# ATA8510 device description
Architecture: AVR8; Family: megaAVR
Registers are 8-bit, access not given, no defined reset value unless marked. A register's access mark holds for its fields unless they carry their own. Offsets are from the block's base; [hi:lo] are bit positions; {n}, {i} and the like mark numbered series.

## SUP
Instances: SUP 0x00
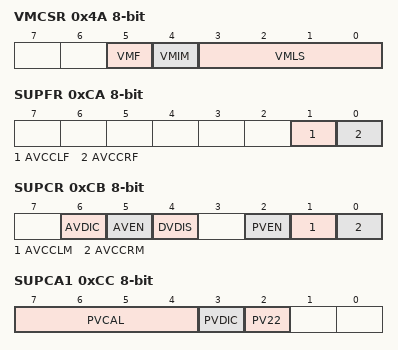
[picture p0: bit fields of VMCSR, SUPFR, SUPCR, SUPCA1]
0x4A VMCSR — Voltage Monitor Control and Status Register
  [5] VMF — Voltage Monitor Flag
  [4] VMIM — Voltage Monitor Interrupt Mask
  [3:0] VMLS — Voltage Monitor Level Select
0xCA SUPFR — Supply Interrupt Flag Register
  [1] AVCCLF — AVCC low interrupt flag
  [0] AVCCRF — AVCC reset interrupt flag
0xCB SUPCR — Supply Control Register
  [6] AVDIC — AVCC Double Internal Current
  [5] AVEN — AVCC Enable
  [4] DVDIS — DVCC Disable
  [2] PVEN — Power amplifier Voltage supply Enable
  [1] AVCCLM — AVCC Low Interrupt Mask Bit
  [0] AVCCRM — AVCC Reset Interrupt Mask Bit
0xCC SUPCA1 — Supply calibration register 1
  [7:4] PVCAL — Power Amplifier Regulator Calibration
  [3] PVDIC — Power Amplifier Regulator Double Internal Current
  [2] PV22 — Power Amplifier Voltage 2.2V
0xCD SUPCA2 — Supply calibration register 2
  [3:0] BGCAL — Band Gap Calibration
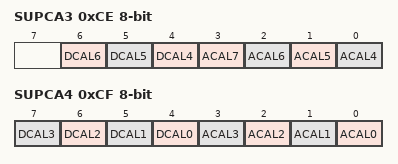
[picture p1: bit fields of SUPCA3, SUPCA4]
0xCE SUPCA3 — Supply calibration register 3
  [6] DCAL6 — DVCC Reset Threshold Calibration bit 6
  [5] DCAL5 — DVCC Reset Threshold Calibration bit 5
  [4] DCAL4 — DVCC Reset Threshold Calibration bit 4
  [n-4] ACAL{n} (n=4..7) — AVCC Reset Threshold Calibration bit {n}
0xCF SUPCA4 — Supply calibration register 4
  [n+4] DCAL{n} (n=0..3) — DVCC Regulator Output Voltage Calibration bit {n}
  [n] ACAL{n} (n=0..3) — AVCC Regulator Output Voltage Calibration bit {n}
0xD0 CALRDY — Calibration ready signature
0xD1 VMCAL — Voltage Monitor Calibration register
  [2:0] VMCAL — Voltage monitor calibration

## SYMCH
Instances: SYMCH 0x00
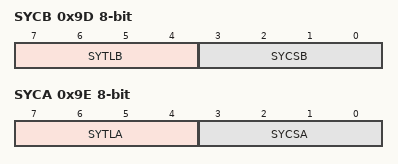
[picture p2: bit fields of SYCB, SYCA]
0x9D SYCB — Symbol check configuration for data path B
  [7:4] SYTLB — Symbol timing limit for path B
  [3:0] SYCSB — Symbol Check check size for data path B
0x9E SYCA — Symbol check configuration for data path A
  [7:4] SYTLA — Symbol timing limit for path A
  [3:0] SYCSA — Symbol Check check size for data path A

## TEMPER
Instances: TEMPER 0x00
0x9B TEMPL — Temperature Low byte
0x9C TEMPH — Temperature High byte

## TIMER0_WDT
Instances: TIMER0_WDT 0x00
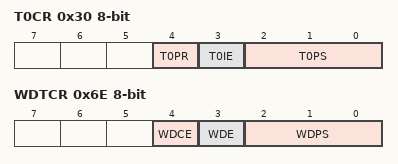
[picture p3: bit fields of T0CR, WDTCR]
0x30 T0CR — Timer0 Control Register
  [4] T0PR — Timer 0 Prescaler Reset
  [3] T0IE — Timer 0 Interrupt Enable
  [2:0] T0PS — Timer 0 Prescaler Select
0x4F T0IFR — Timer0 Interrupt Flag Register
  [0] T0F — Timer0 Flag
0x6E WDTCR — Watchdog Timer0 control Register
  [4] WDCE — Watchdog Change Enable
  [3] WDE — Watchdog System Reset Enable
  [2:0] WDPS — Watchdog Prescaler Select

## TIMER1
Instances: TIMER1 0x00
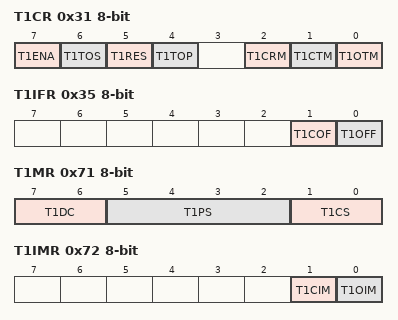
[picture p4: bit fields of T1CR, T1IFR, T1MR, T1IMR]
0x31 T1CR — Timer1 control Register
  [7] T1ENA — Timer1 Enable
  [6] T1TOS — Timer1 Toggle with Start
  [5] T1RES — Timer1 Reset
  [4] T1TOP — Timer1 Toggle Output Preset
  [2] T1CRM — Timer1 Compare Reset Mask
  [1] T1CTM — Timer1 Compare Toggle Mask
  [0] T1OTM — Timer1 Overflow Toggle Mask
0x35 T1IFR — Timer1 Interrupt Flag Register
  [1] T1COF — Timer1 Compare Flag
  [0] T1OFF — Timer1 Overflow Flag
0x6F T1CNT — Timer1 Counter Register
0x70 T1COR — Timer1 Compare Register
0x71 T1MR — Timer1 Mode Register
  [7:6] T1DC — Timer1 Duty Cycle
  [5:2] T1PS — Timer1 Prescaler Select
  [1:0] T1CS — Timer1 Clock Select
    0=clk_src; 1=clk_frc; 2=clk_T; 3=clk_xto4
0x72 T1IMR — Timer1 Interrupt Mask Register
  [1] T1CIM — Timer1 Compare Interrupt Mask
  [0] T1OIM — Timer1 Overflow Interrupt Mask

## TIMER2
Instances: TIMER2 0x00
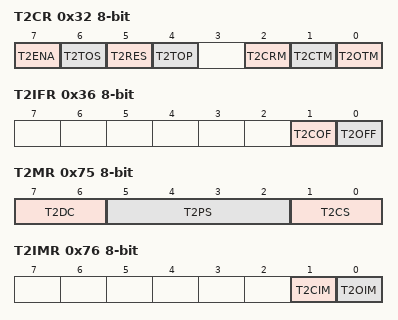
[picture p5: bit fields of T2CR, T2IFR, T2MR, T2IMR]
0x32 T2CR — Timer2 Control Register
  [7] T2ENA — Timer2 Enable
  [6] T2TOS — Timer2 Toggle with Start
  [5] T2RES — Timer2 Reset
  [4] T2TOP — Timer2 Toggle Output Preset
  [2] T2CRM — Timer2 Compare Reset Mask
  [1] T2CTM — Timer2 Compare Toggle Mask
  [0] T2OTM — Timer2 Overflow Toggle Mask
0x36 T2IFR — Timer2 Interrupt Flag Register
  [1] T2COF — Timer2 Compare Flag
  [0] T2OFF — Timer2 Overflow Flag
0x73 T2CNT — Timer2 Counter Register
0x74 T2COR — Timer2 Compare Register
0x75 T2MR — Timer2 Mode Register
  [7:6] T2DC — Timer2 Duty Cycle
  [5:2] T2PS — Timer2 Prescaler Select
  [1:0] T2CS — Timer2 Clock Select
    0=clk_src; 1=clk_vdiv; 2=clk_T; 3=clk_xto4
0x76 T2IMR — Timer2 Interrupt Mask Register
  [1] T2CIM — Timer2 Compare Interrupt Mask
  [0] T2OIM — Timer2 Overflow Interrupt Mask
